# CY8C4248AZI_L485 register map
File version: 0.1
Registers are 32-bit, read-write, no defined reset value unless marked. A register's access mark holds for its fields unless they carry their own. Offsets are from the block's base; [hi:lo] are bit positions; {n}, {i} and the like mark numbered series.

## CAN
Base 0x00000000
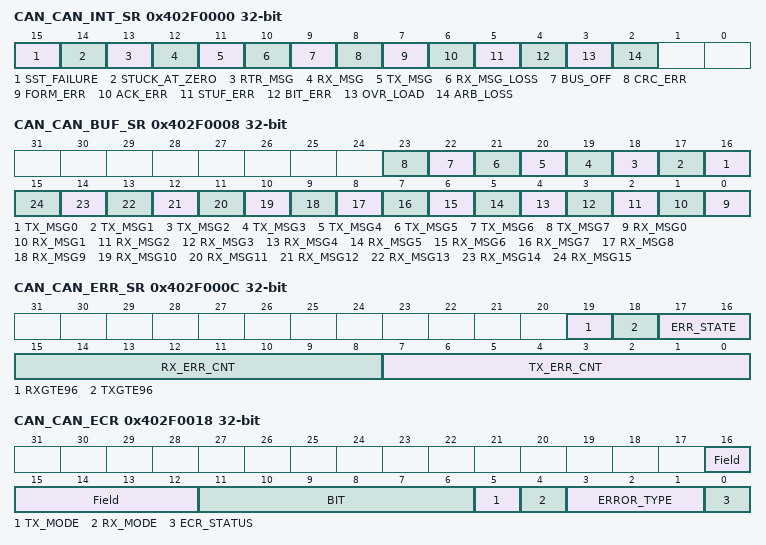
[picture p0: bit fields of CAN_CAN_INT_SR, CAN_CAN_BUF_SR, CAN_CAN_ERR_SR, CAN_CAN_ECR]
0x402F0000 CAN_CAN_INT_SR — The interrupt status register stores internal interrupt events. ? Once a bit is set it remains set until it is cleared by writing a '1' to it. ? The interrupt enable register has no effect on the interrupt status register. ? A pending interrupt occurs when the flag is set to '1'. To acknowledge an interrupt, set the flag to '1'
  [15] SST_FAILURE — Single shot transmission failure
  [14] STUCK_AT_ZERO — Stuck at dominant error
  [13] RTR_MSG — RTR auto-reply message sent
  [12] RX_MSG — Msg Recieved
  [11] TX_MSG — Tx msg Sent
  [10] RX_MSG_LOSS — Rx msg loss Interrupt
  [9] BUS_OFF — Bus Off State
  [8] CRC_ERR — CRC Error Interrupt
  [7] FORM_ERR — Form Error Interrupt
  [6] ACK_ERR — Ack Error Interrupt
  [5] STUF_ERR — Stuff Error Interrupt
  [4] BIT_ERR — Bit Error Interrupt
  [3] OVR_LOAD — Overload Interrupt
  [2] ARB_LOSS — Arbitration Loss
0x402F0008 CAN_CAN_BUF_SR — These status indicators bundle the respective flags from all RxMessage and TxMessage buffers. ? Note All flags are read only. To acknowledge a MsgAv flag, the CPU must write to the respective RxMessage buffer
  [n+16] TX_MSG{n} (n=0..7) — Tx req Pending for Tx Msg{n}
  [n] RX_MSG{n} (n=0..15) — Rx Msg{n} Available
0x402F000C CAN_CAN_ERR_SR — Status indicators are provided to report the CAN controller error state, receive error count, and transmit error count. ? Special flags report error counter values equal to or in excess of 96 errors are available to indicate heavily disturbed bus situations. ? The transmitter error counter according to the CAN standard. When it is greater than 255 Decimal, it is fixed at 255 Decimal.
  [19] RXGTE96 — Rx Error Count is greater or equal to 96 Decimal
  [18] TXGTE96 — Tx Error Count is greater or equal to 96 Decimal
  [17:16] ERR_STATE — Error State of CAN node, 00 error active, 01 error passive, 1x bus off
  [15:8] RX_ERR_CNT — Rx error Count. When in bus-off state,this counter is used to count 128 groups of 11 recessive bits
  [7:0] TX_ERR_CNT — Tx error Count
0x402F0018 CAN_CAN_ECR — The Error Capture register operates in two different modes: ? Free running mode - ECR displays the fiels and bit positions within the current CAN frame ? Error Capture mode - ECR samples the field and bit position when a CAN error is detected ? In order to sample such an event, the ECR needs to be armed by performing a write access to it. ? When armed, the ECR only captures one error event. ? For successive error captures, the ECR needs to be armed again.
  [16:12] Field ro — Field: ? 0x00 : Stopped ? 0x01 : Synchronize ? 0x05 : Interframe ? 0x06 : Bus Idle ? 0x07 : Start of Frame ? 0x08 : Arbitration ? 0x09 : Control ? 0x0A : Data ? 0x0B : CRC ? 0x0C : ACK ? 0x0D : End of frame ? 0x10 : Error flag ? 0x11 : Error echo ? 0x12 : Error delimiter ? 0x18 : Overload flag ? 0x19 : Overload echo ? 0x1A : Overload delimiter ? Others : N/A
  [11:6] BIT ro — Bit number inside of Field
  [5] TX_MODE ro — TX Mode: ? 0: No status ? 1: CAN Controller is transmitter
  [4] RX_MODE ro — RX Mode: ? 0: No status ? 1: CAN Controller is receiver
  [3:1] ERROR_TYPE ro — Error type: ? 000 : Arbitration loss ? 001 : Bit Error ? 010 : Bit Stuffing Error ? 011 : Acknowledge Error ? 100 : Form Error ? 101 : CRC Error ? Others : N/A
  [0] ECR_STATUS — ECR STATUS: ? 0: ECR register captured an error, or it is in free running mode ? 1: ECR register is armed
{0x402F0024+0x10*i} CAN_CAN_TX{i}_ID (i=0..7) — CAN Tx Msg Identifier
  [31:3] ID — Tx Msg Indentifier
{0x402F0028+0x10*i} CAN_CAN_TX{i}_DH (i=0..7) — CAN Tx Msg Upper Data Bytes
  [31:0] DATA_HIGH — Upper Data Bytes
{0x402F002C+0x10*i} CAN_CAN_TX{i}_DL (i=0..7) — CAN Tx Msg Lower Data Bytes
  [31:0] DATA_LOW — Lower Data Bytes
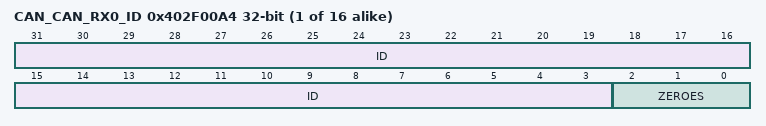
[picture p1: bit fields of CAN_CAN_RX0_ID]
{0x402F00A4+0x20*i} CAN_CAN_RX{i}_ID (i=0..15) — The register contains Rx Msg Identifier
  [31:3] ID — Rx Msg Indentifier
  [2:0] ZEROES — zeros
{0x402F00A8+0x20*i} CAN_CAN_RX{i}_DH (i=0..15) — The register contains the Rx Msg Upper Data Bytes
  [31:0] DATA_HIGH — Upper Data Bytes
{0x402F00AC+0x20*i} CAN_CAN_RX{i}_DL (i=0..15) — The register contains the Rx Msg Lover Data Bytes
  [31:0] DATA_LOW — Lower Data Bytes

## ADC_3_Buffer — OpAmp
Base 0x00000000
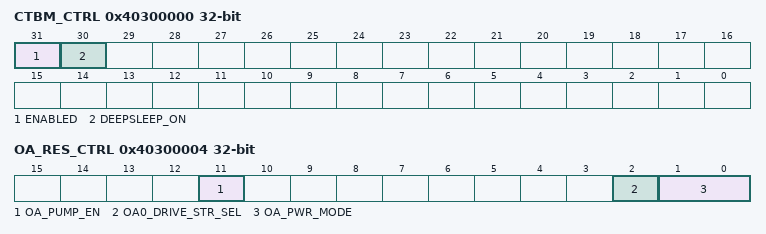
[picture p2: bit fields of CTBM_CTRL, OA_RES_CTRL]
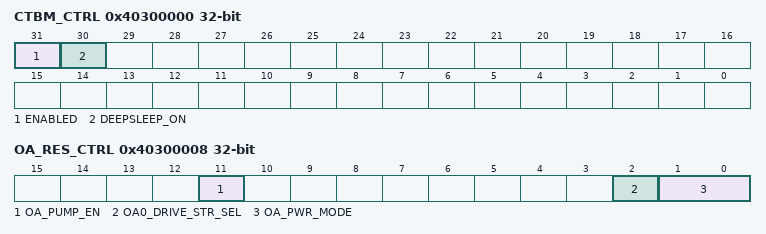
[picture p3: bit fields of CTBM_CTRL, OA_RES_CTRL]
0x40300000 CTBM_CTRL — Global CTB IP and power control
  [31] ENABLED — Selects component behavior in DeepSleep power mode
    0=DISABLE (CTB IP disabled (put analog in power down, open all switches)); 1=ENABLE (CTB IP enabledCTB IP enabled)
  [30] DEEPSLEEP_ON — Selects component behavior in DeepSleep power mode
    0=DISABLE (CTB IP disabled off during DeepSleep power mode); 1=ENABLE (CTB IP remains enabled during DeepSleep power mode (if ENABLED=1))
0x40300004 OA_RES_CTRL — Opamp and resistor control
  [11] OA_PUMP_EN — Selects pump
    0=DISABLE (Pump disabled); 1=ENABLE (Pump enabled)
  [2] OA0_DRIVE_STR_SEL — Opamp output strenght select
    0=Cy1x (Internal only); 1=Cy10x (Output to pin)
  [1:0] OA_PWR_MODE — Selects power for opamp
    0=OFF; 1=LOW (Low power); 2=MED (Medium power); 3=HIGH (High power)
0x40300F08 OA_COMP_TRIM — Opamp Compenation Capacitor Trim
  [1:0] OA_COMP_TRIM
    1=HIGH_SPEED; 2=BALANCED; 3=HIGH_STABILITY

## ADC_2_Buffer — OpAmp
Base 0x00000000
0x40300000 CTBM_CTRL — Global CTB IP and power control
  [31] ENABLED — Selects component behavior in DeepSleep power mode
    0=DISABLE (CTB IP disabled (put analog in power down, open all switches)); 1=ENABLE (CTB IP enabledCTB IP enabled)
  [30] DEEPSLEEP_ON — Selects component behavior in DeepSleep power mode
    0=DISABLE (CTB IP disabled off during DeepSleep power mode); 1=ENABLE (CTB IP remains enabled during DeepSleep power mode (if ENABLED=1))
0x40300008 OA_RES_CTRL — Opamp and resistor control
  [11] OA_PUMP_EN — Selects pump
    0=DISABLE (Pump disabled); 1=ENABLE (Pump enabled)
  [2] OA0_DRIVE_STR_SEL — Opamp output strenght select
    0=Cy1x (Internal only); 1=Cy10x (Output to pin)
  [1:0] OA_PWR_MODE — Selects power for opamp
    0=OFF; 1=LOW (Low power); 2=MED (Medium power); 3=HIGH (High power)
0x40300F14 OA_COMP_TRIM — Opamp Compenation Capacitor Trim
  [1:0] OA_COMP_TRIM
    1=HIGH_SPEED; 2=BALANCED; 3=HIGH_STABILITY

## CapSense_IDAC1 — IDAC
Base 0x00000000
Same registers: CapSense_IDAC2 0x00000000
0x40280004 CSD_IDAC_POLARITY
0x40280008 CSD_IDAC
0x4028FF00 CSD_TRIM1 — CSD IDAC TRIM1
0x4028FF04 CSD_TRIM2 — CSD IDAC TRIM2
